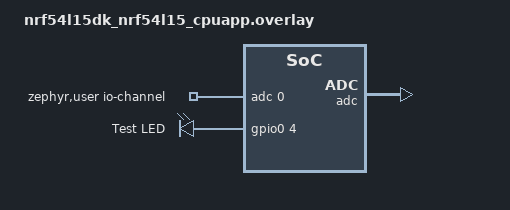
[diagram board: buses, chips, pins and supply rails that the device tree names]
//GPIO
/ {
    zephyr,user {
        io-channels = <&adc 0>;
    };
    
    aliases {
        led0 = &led0;
    };
    
    leds {
        compatible = "gpio-leds";
        led0: led_0 {
            gpios = <&gpio0 4 GPIO_ACTIVE_HIGH>; /* P0.04 - adjust pin as needed */
            label = "Test LED";
        };
    };
};

&adc {
 status = "okay";
};
